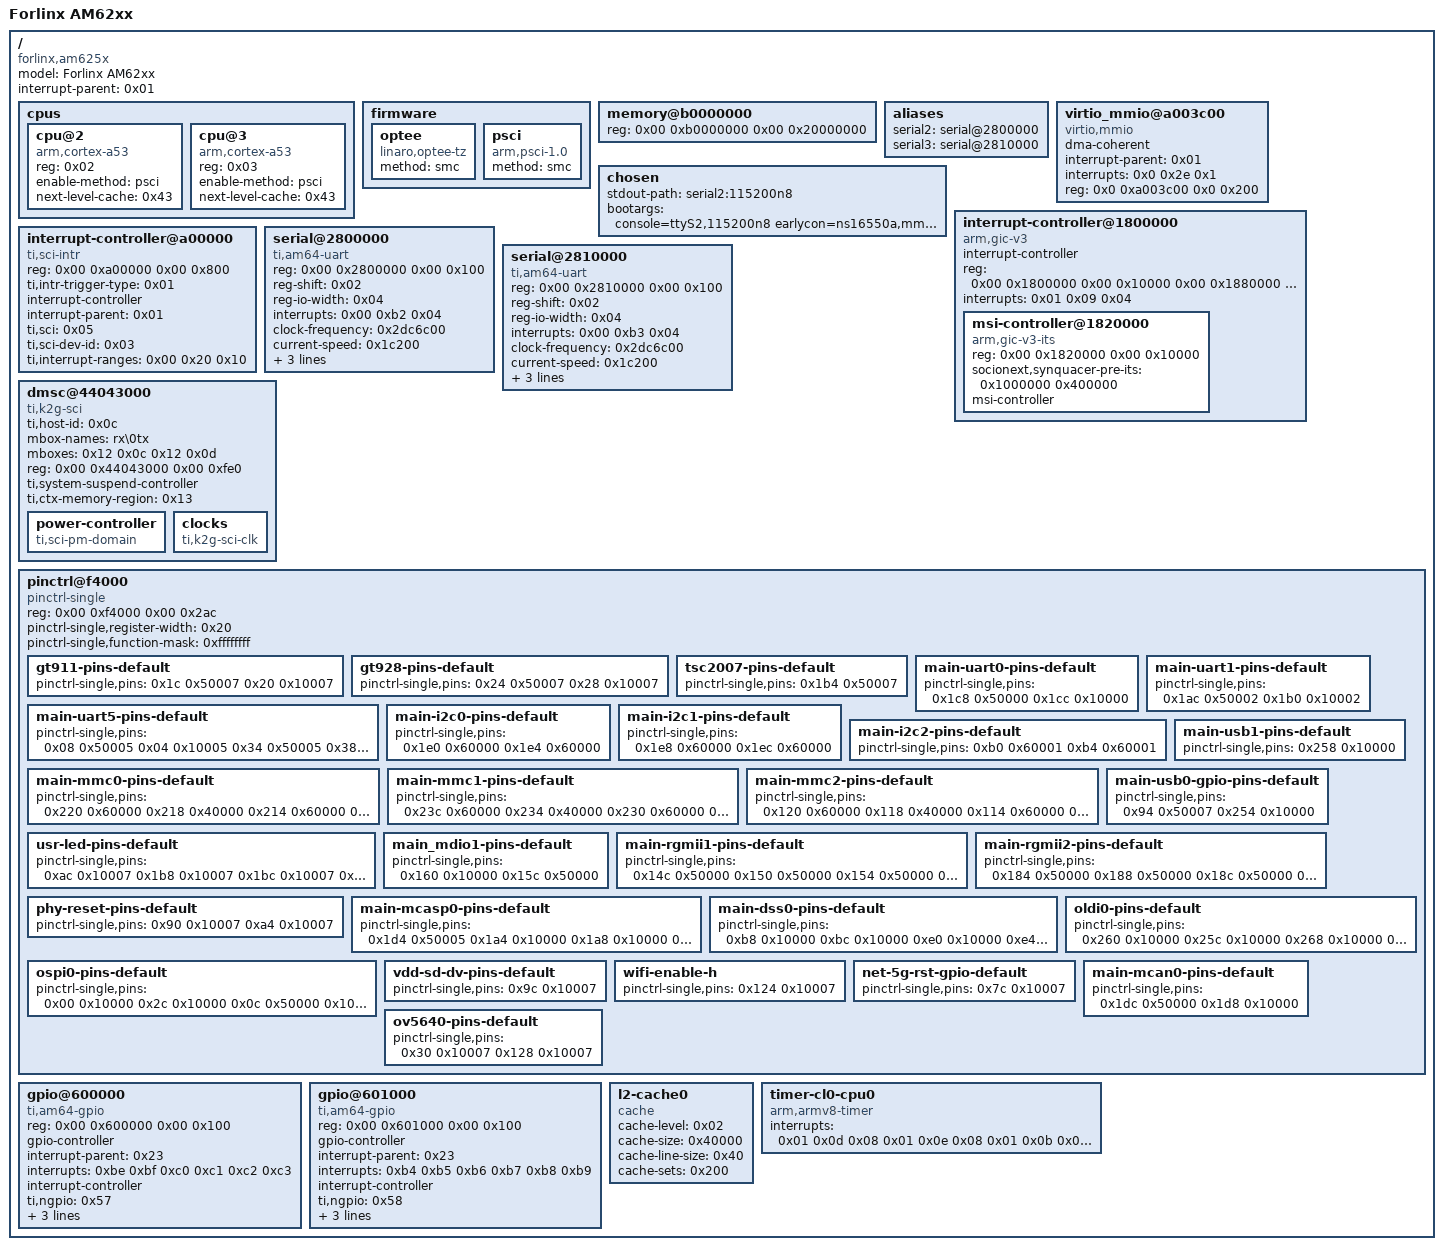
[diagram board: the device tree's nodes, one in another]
/dts-v1/;

/ {
	model = "Forlinx AM62xx";
	compatible = "forlinx,am625x\0ti,am625-sk\0ti,am625";
	interrupt-parent = <0x01>;
	#address-cells = <0x02>;
	#size-cells = <0x02>;
	
	cpus {
		#address-cells = <0x01>;
		#size-cells = <0x00>;
		
		cpu@2 {
			compatible = "arm,cortex-a53";
			reg = <0x02>;
			device_type = "cpu";
			enable-method = "psci";
			next-level-cache = <0x43>;
		};
		
		cpu@3 {
			compatible = "arm,cortex-a53";
			reg = <0x03>;
			device_type = "cpu";
			enable-method = "psci";
			next-level-cache = <0x43>;
		};
	};
	
	firmware {
		optee {
			compatible = "linaro,optee-tz";
			method = "smc";
		};
		
		// PSCI 是 ARM 定义的标准接口，用于管理多核处理器的电源状态
		psci {
			compatible = "arm,psci-1.0";
			method = "smc";
			phandle = <0x4d>;
		};
	};
	
	memory@b0000000 {
		device_type = "memory";
		reg = <0x00 0xb0000000 0x00 0x20000000>;
	};
	
	aliases {
		serial2 = "serial@2800000";
		serial3 = "serial@2810000";
	};
	
	// virtio blk
	virtio_mmio@a003c00 {
		dma-coherent;
		interrupt-parent = <0x01>;
		interrupts = <0x0 0x2e 0x1>;
		reg = <0x0 0xa003c00 0x0 0x200>;
		compatible = "virtio,mmio";
		status = "okay";
	};
	
	
	// virtio serial
	// virtio_mmio@a003800 {
	//    dma-coherent;
	//    interrupt-parent = <0x01>;
	//    interrupts = <0x0 0x2c 0x1>;
	//    reg = <0x0 0xa003800 0x0 0x200>;
	//    compatible = "virtio,mmio";
	// };
	
	chosen {
		// virtio blk and real console:
		// stdout-path = "serial3:115200n8";
		// bootargs = "console=ttyS3,115200n8 earlycon=ns16550a,mmio32,0x02810000 root=/dev/vda rootwait rw";
		
		stdout-path = "serial2:115200n8";
		bootargs = "console=ttyS2,115200n8  earlycon=ns16550a,mmio32,0x02800000 root=/dev/vda rootwait rw";
		
		//stdout-path = "serial3:115200n8";
		//bootargs = "console=ttyS3,115200n8 root=/dev/vda rootwait rw";
		
		
		// virtio blk and virtio console:
		// bootargs = "clk_ignore_unused earlycon=virtio,mmio,0xa003800 console=hvc0 root=/dev/vda rootwait rw";
		// stdout-path = "/virtio_mmio@a003800";
	};
	
	interrupt-controller@1800000 {
		compatible = "arm,gic-v3";
		#address-cells = <0x02>;
		#size-cells = <0x02>;
		ranges;
		#interrupt-cells = <0x03>;
		interrupt-controller;
		reg = <0x00 0x1800000 0x00 0x10000 0x00 0x1880000 0x00 0xc0000>;
		interrupts = <0x01 0x09 0x04>;
		phandle = <0x01>;

		msi-controller@1820000 {
			compatible = "arm,gic-v3-its";
			reg = <0x00 0x1820000 0x00 0x10000>;
			socionext,synquacer-pre-its = <0x1000000 0x400000>;
			msi-controller;
			#msi-cells = <0x01>;
			phandle = <0x63>;
		};
	};

	interrupt-controller@a00000 {
		compatible = "ti,sci-intr";
		reg = <0x00 0xa00000 0x00 0x800>;
		ti,intr-trigger-type = <0x01>;
		interrupt-controller;
		interrupt-parent = <0x01>;
		#interrupt-cells = <0x01>;
		ti,sci = <0x05>;
		ti,sci-dev-id = <0x03>;
		ti,interrupt-ranges = <0x00 0x20 0x10>;
		phandle = <0x23>;
	};

	serial@2800000 {
		compatible = "ti,am64-uart\0ti,am654-uart";
		reg = <0x00 0x2800000 0x00 0x100>;
		reg-shift = <0x02>;
		reg-io-width = <0x04>;
		// 0x00 通常表示 SPI 0xb2 是设备的中断号 0x04 通常表示边沿触发
		interrupts = <0x00 0xb2 0x04>;
		clock-frequency = <0x2dc6c00>;
		current-speed = <0x1c200>;
		power-domains = <0x02 0x92 0x01>;
		clocks = <0x03 0x92 0x00>;
		clock-names = "fclk";
		pinctrl-names = "default";
		pinctrl-0 = <0x14>;
		phandle = <0x6b>;
	};
	
	serial@2810000 {
		compatible = "ti,am64-uart\0ti,am654-uart";
		reg = <0x00 0x2810000 0x00 0x100>;
		reg-shift = <0x02>;
		reg-io-width = <0x04>;
		interrupts = <0x00 0xb3 0x04>;
		clock-frequency = <0x2dc6c00>;
		current-speed = <0x1c200>;
		power-domains = <0x02 0x98 0x01>;
		clocks = <0x03 0x98 0x00>;
		clock-names = "fclk";
		pinctrl-names = "default";
		pinctrl-0 = <0x15>;
		status = "okay";
		phandle = <0x6c>;
	};
	
	dmsc@44043000 {
		compatible = "ti,k2g-sci";
		ti,host-id = <0x0c>;
		mbox-names = "rx\0tx";
		mboxes = <0x12 0x0c 0x12 0x0d>;
		reg-names = "debug_messages";
		reg = <0x00 0x44043000 0x00 0xfe0>;
		ti,system-suspend-controller;
		ti,ctx-memory-region = <0x13>;
		phandle = <0x05>;
		
		power-controller {
			compatible = "ti,sci-pm-domain";
			#power-domain-cells = <0x02>;
			phandle = <0x02>;
		};
		
		clocks {
			compatible = "ti,k2g-sci-clk";
			#clock-cells = <0x02>;
			phandle = <0x03>;
		};
		
	};
	

	pinctrl@f4000 {
		compatible = "pinctrl-single";
		reg = <0x00 0xf4000 0x00 0x2ac>;
		#pinctrl-cells = <0x01>;
		pinctrl-single,register-width = <0x20>;
		pinctrl-single,function-mask = <0xffffffff>;
		phandle = <0x68>;
		gt911-pins-default {
			pinctrl-single,pins = <0x1c 0x50007 0x20 0x10007>;
			phandle = <0x1f>;
		};

		gt928-pins-default {
			pinctrl-single,pins = <0x24 0x50007 0x28 0x10007>;
			phandle = <0x22>;
		};

		tsc2007-pins-default {
			pinctrl-single,pins = <0x1b4 0x50007>;
			phandle = <0x1d>;
		};

		main-uart0-pins-default {
			pinctrl-single,pins = <0x1c8 0x50000 0x1cc 0x10000>;
			phandle = <0x14>;
		};

		main-uart1-pins-default {
			pinctrl-single,pins = <0x1ac 0x50002 0x1b0 0x10002>;
			phandle = <0x15>;
		};

		main-uart5-pins-default {
			pinctrl-single,pins = <0x08 0x50005 0x04 0x10005 0x34 0x50005 0x38 0x10005>;
			phandle = <0x16>;
		};

		main-i2c0-pins-default {
			pinctrl-single,pins = <0x1e0 0x60000 0x1e4 0x60000>;
			phandle = <0x17>;
		};

		main-i2c1-pins-default {
			pinctrl-single,pins = <0x1e8 0x60000 0x1ec 0x60000>;
			phandle = <0x18>;
		};

		main-i2c2-pins-default {
			pinctrl-single,pins = <0xb0 0x60001 0xb4 0x60001>;
			phandle = <0x20>;
		};

		main-mmc0-pins-default {
			pinctrl-single,pins = <0x220 0x60000 0x218 0x40000 0x214 0x60000 0x210 0x60000 0x20c 0x60000 0x208 0x60000 0x204 0x60000 0x200 0x60000 0x1fc 0x60000 0x1f8 0x60000>;
			phandle = <0x24>;
		};

		main-mmc1-pins-default {
			pinctrl-single,pins = <0x23c 0x60000 0x234 0x40000 0x230 0x60000 0x22c 0x60000 0x228 0x60000 0x224 0x60000 0x240 0x60000>;
			phandle = <0x27>;
		};

		main-mmc2-pins-default {
			pinctrl-single,pins = <0x120 0x60000 0x118 0x40000 0x114 0x60000 0x110 0x60000 0x10c 0x60000 0x108 0x60000 0x11c 0x50000>;
			phandle = <0x28>;
		};

		usr-led-pins-default {
			pinctrl-single,pins = <0xac 0x10007 0x1b8 0x10007 0x1bc 0x10007 0x1c0 0x10007 0x1c4 0x10007>;
			phandle = <0x4a>;
		};

		main-usb1-pins-default {
			pinctrl-single,pins = <0x258 0x10000>;
			phandle = <0x35>;
		};

		main-usb0-gpio-pins-default {
			pinctrl-single,pins = <0x94 0x50007 0x254 0x10000>;
			phandle = <0x33>;
		};

		main_mdio1-pins-default {
			pinctrl-single,pins = <0x160 0x10000 0x15c 0x50000>;
			phandle = <0x2b>;
		};

		main-rgmii1-pins-default {
			pinctrl-single,pins = <0x14c 0x50000 0x150 0x50000 0x154 0x50000 0x158 0x50000 0x148 0x50000 0x144 0x50000 0x134 0x10000 0x138 0x10000 0x13c 0x10000 0x140 0x10000 0x130 0x10000 0x12c 0x10000>;
			phandle = <0x2c>;
		};

		main-rgmii2-pins-default {
			pinctrl-single,pins = <0x184 0x50000 0x188 0x50000 0x18c 0x50000 0x190 0x50000 0x180 0x50000 0x17c 0x50000 0x16c 0x10000 0x170 0x10000 0x174 0x10000 0x178 0x10000 0x168 0x10000 0x164 0x10000>;
			phandle = <0x2d>;
		};

		phy-reset-pins-default {
			pinctrl-single,pins = <0x90 0x10007 0xa4 0x10007>;
			phandle = <0x2e>;
		};

		main-mcasp0-pins-default {
			pinctrl-single,pins = <0x1d4 0x50005 0x1a4 0x10000 0x1a8 0x10000 0x198 0x10000 0x194 0x50000>;
			phandle = <0x3d>;
		};

		main-dss0-pins-default {
			pinctrl-single,pins = <0xb8 0x10000 0xbc 0x10000 0xe0 0x10000 0xe4 0x10000 0xe8 0x10000 0xec 0x10000 0xf0 0x10000 0xf4 0x10000 0xc0 0x10000 0xc4 0x10000 0xc8 0x10000 0xcc 0x10000 0xd0 0x10000 0xd4 0x10000 0xd8 0x10000 0xdc 0x10000 0xfc 0x10000 0xf8 0x10000 0x104 0x10000 0x100 0x10000>;
			phandle = <0x69>;
		};

		oldi0-pins-default {
			pinctrl-single,pins = <0x260 0x10000 0x25c 0x10000 0x268 0x10000 0x264 0x10000 0x270 0x10000 0x26c 0x10000 0x278 0x10000 0x274 0x10000 0x280 0x10000 0x27c 0x10000 0x288 0x10000 0x284 0x10000 0x290 0x10000 0x28c 0x10000 0x298 0x10000 0x294 0x10000 0x2a0 0x10000 0x29c 0x10000 0x2a8 0x10000 0x2a4 0x10000>;
			phandle = <0x6a>;
		};

		ospi0-pins-default {
			pinctrl-single,pins = <0x00 0x10000 0x2c 0x10000 0x0c 0x50000 0x10 0x50000 0x14 0x50000 0x18 0x50000>;
			phandle = <0x2a>;
		};

		vdd-sd-dv-pins-default {
			pinctrl-single,pins = <0x9c 0x10007>;
			phandle = <0x49>;
		};

		wifi-enable-h {
			pinctrl-single,pins = <0x124 0x10007>;
			phandle = <0x48>;
		};

		net-5g-rst-gpio-default {
			pinctrl-single,pins = <0x7c 0x10007>;
			phandle = <0x47>;
		};

		main-mcan0-pins-default {
			pinctrl-single,pins = <0x1dc 0x50000 0x1d8 0x10000>;
			phandle = <0x3c>;
		};

		ov5640-pins-default {
			pinctrl-single,pins = <0x30 0x10007 0x128 0x10007>;
			phandle = <0x19>;
		};
	};

	gpio@600000 {
		compatible = "ti,am64-gpio\0ti,keystone-gpio";
		reg = <0x00 0x600000 0x00 0x100>;
		gpio-controller;
		#gpio-cells = <0x02>;
		interrupt-parent = <0x23>;
		interrupts = <0xbe 0xbf 0xc0 0xc1 0xc2 0xc3>;
		interrupt-controller;
		#interrupt-cells = <0x02>;
		ti,ngpio = <0x57>;
		ti,davinci-gpio-unbanked = <0x00>;
		power-domains = <0x02 0x4d 0x01>;
		clocks = <0x03 0x4d 0x00>;
		clock-names = "gpio";
		phandle = <0x1b>;
	};

	gpio@601000 {
		compatible = "ti,am64-gpio\0ti,keystone-gpio";
		reg = <0x00 0x601000 0x00 0x100>;
		gpio-controller;
		#gpio-cells = <0x02>;
		interrupt-parent = <0x23>;
		interrupts = <0xb4 0xb5 0xb6 0xb7 0xb8 0xb9>;
		interrupt-controller;
		#interrupt-cells = <0x02>;
		ti,ngpio = <0x58>;
		ti,davinci-gpio-unbanked = <0x00>;
		power-domains = <0x02 0x4e 0x01>;
		clocks = <0x03 0x4e 0x00>;
		clock-names = "gpio";
		phandle = <0x1e>;
	};

	
	l2-cache0 {
		compatible = "cache";
		cache-level = <0x02>;
		cache-size = <0x40000>;
		cache-line-size = <0x40>;
		cache-sets = <0x200>;
	};
	
	timer-cl0-cpu0 {
		compatible = "arm,armv8-timer";
		interrupts = <0x01 0x0d 0x08
		0x01 0x0e 0x08
		0x01 0x0b 0x08
		0x01 0x0a 0x08>;
		phandle = <0x4e>;
	};
	
	
};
